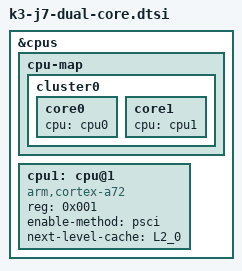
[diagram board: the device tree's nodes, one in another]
// SPDX-License-Identifier: GPL-2.0
/*
 * Device Tree Source for Jacinto7 SoC (dual core variant)
 *
 * Copyright (C) 2017 Texas Instruments Incorporated - http://www.ti.com/
 */

&cpus {
	cpu-map {
		cluster0: cluster0 {
			core0 {
				cpu = <&cpu0>;
			};

			core1 {
				cpu = <&cpu1>;
			};
		};

	};

	/* CPU0 is already defined */

	cpu1: cpu@1 {
		compatible = "arm,cortex-a72","arm,armv8";
		reg = <0x001>;
		device_type = "cpu";
		enable-method = "psci";
		next-level-cache = <&L2_0>;
	};
};
